# RA6M2 register map
Vendor: Renesas Electronics Corporation; Series: RA6; File version: 1.1
CPU: CM4 r0p1, little endian, MPU, FPU, VTOR, 4 interrupt priority bits
Registers are 8-bit, read-write, reset 0x0 unless marked. A register's access mark holds for its fields unless they carry their own. Offsets are from the block's base; [hi:lo] are bit positions; 'fields as' and 'values as' point back to an identical list.

## PDC — Parallel Data Capture Unit
Base 0x40094000
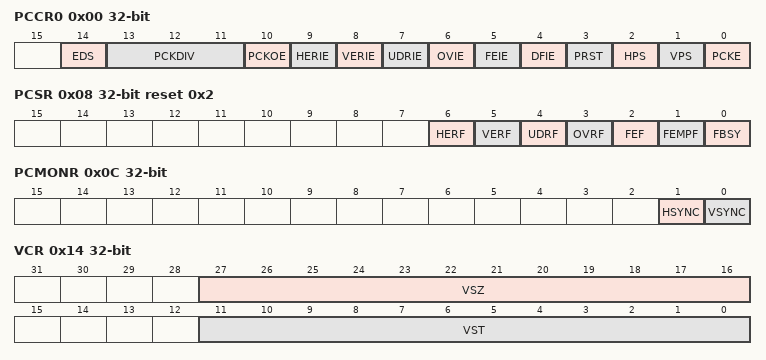
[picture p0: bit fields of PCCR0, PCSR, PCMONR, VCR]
0x00 PCCR0 32-bit — PDC Control Register 0
  [14] EDS — Endian Select
    0=Little endian; 1=Big endian
  [13:11] PCKDIV — PCKO Frequency Division Ratio Select
    0=PCKO/2; 1=PCKO/4; 2=PCKO/6; 3=PCKO/8; 4=PCKO/10; 5=PCKO/12; 6=PCKO/14; 7=PCKO/16
  [10] PCKOE — PCKO Output Enable
    0=PCKO output is disabled (fixed to the high level); 1=PCKO output is enabled
  [9] HERIE — Horizontal Byte Number Setting Error Interrupt Enable
    0=Generation of horizontal byte number setting error interrupt requests is disabled; 1=Generation of horizontal byte number setting error interrupt requests is enabled
  [8] VERIE — Vertical Line Number Setting Error Interrupt Enable
    0=Generation of vertical line number setting error interrupt requests is disabled; 1=Generation of vertical line number setting error interrupt requests is enabled
  [7] UDRIE — Underrun Interrupt Enable
    0=Generation of underrun interrupt requests is disabled; 1=Generation of underrun interrupt requests is enabled
  [6] OVIE — Overrun Interrupt Enable
    0=Generation of overrun interrupt requests is disabled; 1=Generation of overrun interrupt requests is enabled
  [5] FEIE — Frame End Interrupt Enable
    0=Generation of frame end interrupt requests is disabled; 1=Generation of frame end interrupt requests is enabled
  [4] DFIE — Receive Data Ready Interrupt Enable
    0=Generation of receive data ready interrupt requests is disabled; 1=Generation of receive data ready interrupt requests is enabled
  [3] PRST — PDC Reset
    0=PDC reset is not applied; 1=PDC is reset
  [2] HPS — HSYNC Signal Polarity Select
    0=HSYNC signal is active high; 1=HSYNC signal is active low
  [1] VPS — VSYNC Signal Polarity Select
    0=VSYNC signal is active high; 1=VSYNC signal is active low
  [0] PCKE — Channel 0 GTCNT Count Clear
    0=Operations for reception are stopped; 1=Operations for reception are ongoing
0x04 PCCR1 32-bit — PDC Control Register 1
  [0] PCE — PDC Operation Enable
    0=Operations for reception are disabled; 1=Operations for reception are enabled
0x08 PCSR 32-bit reset 0x2 — PDC Status Register
  [6] HERF write-0-clears read-modifies — Horizontal Byte Number Setting Error Flag
    0=Horizontal byte number setting error has not been generated; 1=Horizontal byte number setting error has been generated
  [5] VERF write-0-clears read-modifies — Vertical Line Number Setting Error Flag
    0=Vertical line number setting error has not been generated; 1=Vertical line number setting error has been generated
  [4] UDRF write-0-clears read-modifies — Underrun Flag
    0=Underrun has not been generated; 1=Underrun has been generated
  [3] OVRF write-0-clears read-modifies — Overrun Flag
    0=FIFO overrun has not been generated; 1=FIFO overrun has been generated
  [2] FEF write-0-clears read-modifies — Frame End Flag
    0=Frame end has not been generated; 1=Frame end has been generated
  [1] FEMPF ro — FIFO Empty Flag
    0=FIFO is not empty; 1=FIFO is empty
  [0] FBSY ro — Frame Busy Flag
    values as PCCR0.PCKE
0x0C PCMONR 32-bit ro — PDC Pin Monitor Register
  [1] HSYNC — HSYNC Signal Status Flag
    0=HSYNC signal is at the low level; 1=HSYNC signal is at the high level
  [0] VSYNC — VSYNC Signal Status Flag
    0=VSYNC signal is at the low level; 1=VSYNC signal is at the high level
0x10 PCDR 32-bit ro — PDC Receive Data Register
  [31:0] PCDR — The PDC includes a 32-bit-wide, 22-stage FIFO for the storage of captured data. The PCDR register is a 4-byte space to which the FIFO is mapped, and four bytes of data are read from the PCDR register at a time.
0x14 VCR 32-bit — Vertical Capture Register
  [27:16] VSZ — Vertical Capture Size Number of lines to be captured.
  [11:0] VST — Vertical Capture Start Line PositionNumber of the line where capture is to start.
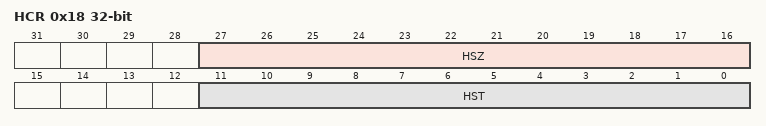
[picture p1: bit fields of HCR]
0x18 HCR 32-bit — Horizontal Capture Register
  [27:16] HSZ — Horizontal Capture Size Number of bytes to capture horizontally.
  [11:0] HST — Horizontal Capture Start Byte Position Horizontal position in bytes where capture is to start.
